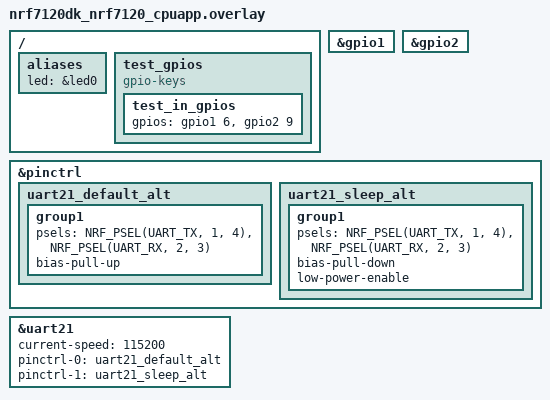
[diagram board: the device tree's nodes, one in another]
/*
 * Copyright (c) 2026 Nordic Semiconductor ASA
 *
 * SPDX-License-Identifier: LicenseRef-Nordic-5-Clause
 */

/*
 * Required loopbacks
 * P1.04 - P1.06
 * P2.03 - P2.09
 */

/ {
	aliases {
		led = &led0;
	};

	test_gpios {
		compatible = "gpio-keys";

		test_in_gpios: test_in_gpios {
			gpios = <&gpio1 6 GPIO_ACTIVE_HIGH>, <&gpio2 9 GPIO_ACTIVE_HIGH>;
		};
	};
};

&gpio1 {
	status = "okay";
};

&gpio2 {
	status = "okay";
};

&pinctrl {
	uart21_default_alt: uart21_default_alt {
		group1 {
			psels = <NRF_PSEL(UART_TX, 1, 4)>,
				<NRF_PSEL(UART_RX, 2, 3)>;
			bias-pull-up;
		};
	};

	uart21_sleep_alt: uart21_sleep_alt {
		group1 {
			psels = <NRF_PSEL(UART_TX, 1, 4)>,
				<NRF_PSEL(UART_RX, 2, 3)>;
			bias-pull-down;
			low-power-enable;
		};
	};
};

dut: &uart21 {
	status = "okay";
	current-speed = <115200>;
	pinctrl-0 = <&uart21_default_alt>;
	pinctrl-1 = <&uart21_sleep_alt>;
	pinctrl-names = "default", "sleep";
	/delete-property/ hw-flow-control;
	/delete-property/ zephyr,pm-device-runtime-auto;
};
